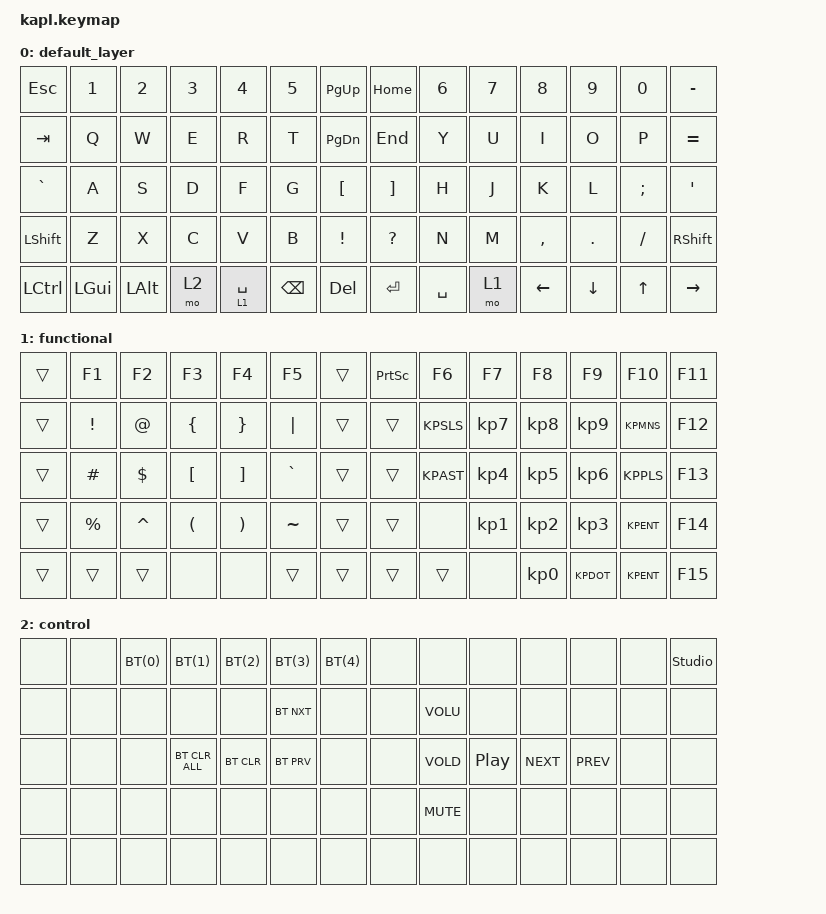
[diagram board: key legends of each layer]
#include <behaviors.dtsi>
#include <dt-bindings/zmk/keys.h>
#include <dt-bindings/zmk/bt.h>

#define FN_SPC &lt 1 SPACE

// for formatting reasons
#define KPAST KP_ASTERISK
#define KPSLS KP_SLASH
#define KPDOT KP_DOT
#define KPMNS KP_MINUS
#define KPPLS KP_PLUS
#define KPENT KP_ENTER

#define C_VOL_UP VOLU
#define C_VOL_DN VOLD
#define C_MUTE MUTE
#define C_NEXT NEXT
#define C_PREV PREV

#define BTC &bt BT_CLR
#define BTCA &bt BT_CLR_ALL
#define BTN &bt BT_NXT
#define BTP &bt BT_PRV

#define BT(a) &bt BT_SEL a

/ {
    keymap {
        compatible = "zmk,keymap";

        default_layer { // Layer 0
            // -------------------------------------
            // |    ESC    |     1     |     2     |     3     |     4     |     5     |    PGUP   |           |    HOME   |     6     |     7     |     8     |     9     |     0     |     -     |
            // |    TAB    |     Q     |     W     |     E     |     R     |     T     |    PGDN   |           |    END    |     Y     |     U     |     I     |     O     |     P     |     =     |
            // |     `     |     A     |     S     |     D     |     F     |     G     |     [     |           |     ]     |     H     |     J     |     K     |     L     |     ;     |     '     |
            // |   LSHFT   |     Z     |     X     |     C     |     V     |     B     |     !     |           |     ?     |     N     |     M     |     ,     |     .     |     /     |    RSFT   |
            // |   LCTRL   |    LGUI   |    LALT   |    MO1    |   SPC_FN  | |    BSPC   |    DEL    |       |    ENT    |    SPC    | |    MO1    |    LEFT   |    DOWN   |     UP    |    RGHT   |
            bindings = <
                &kp ESC   &kp N1    &kp N2    &kp N3    &kp N4    &kp N5    &kp PG_UP          &kp HOME  &kp N6    &kp N7    &kp N8    &kp N9    &kp N0    &kp MINUS
                &kp TAB   &kp Q     &kp W     &kp E     &kp R     &kp T     &kp PG_DN          &kp END   &kp Y     &kp U     &kp I     &kp O     &kp P     &kp EQUAL
                &kp GRAVE &kp A     &kp S     &kp D     &kp F     &kp G     &kp LBKT           &kp RBKT  &kp H     &kp J     &kp K     &kp L     &kp SEMI  &kp APOS
                &kp LSHFT &kp Z     &kp X     &kp C     &kp V     &kp B     &kp EXCL           &kp QMARK &kp N     &kp M     &kp COMMA &kp DOT   &kp FSLH  &kp RSHFT
                &kp LCTRL &kp LGUI  &kp LALT  &mo 2     FN_SPC    &kp BSPC  &kp DEL            &kp RET   &kp SPACE &mo 1     &kp LEFT  &kp DOWN  &kp UP    &kp RIGHT
            >;
        };

        functional { // Layer 1
            // -------------------------------------
            // |   trans   |    F1     |    F2     |    F3     |    F4     |    F5     |   trans   |           |   trans   |    F6     |    F7     |    F8     |    F9     |    F10    |    F11    |
            // |   trans   |     !     |     @     |     {     |     }     |     |     |   trans   |           |   trans   |    KP_/   |    KP_7   |    KP_8   |    KP_9   |    KP_-   |    F12    |
            // |   trans   |     #     |     $     |     [     |     ]     |     `     |   trans   |           |   trans   |    KP_*   |    KP_4   |    KP_5   |    KP_6   |    KP_+   |    F13    |
            // |   trans   |     %     |     ^     |     (     |     )     |     ~     |   trans   |           |   trans   |    none   |    KP_1   |    KP_2   |    KP_3   |   KP_ENT  |    F14    |
            // |   trans   |   trans   |   trans   |    none   |    none   | |   trans   |   trans   |       |   trans   |   trans   | |    none   |    KP_0   |    KP_.   |   KP_ENT  |    F15    |
            bindings = <
                &trans    &kp F1    &kp F2    &kp F3    &kp F4    &kp F5    &trans             &kp PSCRN &kp F6    &kp F7    &kp F8    &kp F9    &kp F10   &kp F11
                &trans    &kp EXCL  &kp AT    &kp LBRC  &kp RBRC  &kp PIPE  &trans             &trans    &kp KPSLS &kp KP_N7 &kp KP_N8 &kp KP_N9 &kp KPMNS &kp F12
                &trans    &kp HASH  &kp DLLR  &kp LBKT  &kp RBKT  &kp GRAVE &trans             &trans    &kp KPAST &kp KP_N4 &kp KP_N5 &kp KP_N6 &kp KPPLS &kp F13
                &trans    &kp PRCNT &kp CARET &kp LPAR  &kp RPAR  &kp TILDE &trans             &trans    &none     &kp KP_N1 &kp KP_N2 &kp KP_N3 &kp KPENT &kp F14
                &trans    &trans    &trans    &none     &none     &trans    &trans             &trans    &trans    &none     &kp KP_N0 &kp KPDOT &kp KPENT &kp F15
            >;
        };

        control { // Layer 2
            // -------------------------------------
            // |    none   |    none   |   BT(0)   |   BT(1)   |   BT(2)   |   BT(3)   |   BT(4)   |           |    none   |    none   |    none   |    none   |    none   |    none   |   STUDIO  |
            // |    none   |    none   |    none   |    none   |    none   |   BT_NXT  |    none   |           |    none   |   VOL_UP  |    none   |    none   |    none   |    none   |    none   |
            // |    none   |    none   |    none   | BT_CLR_ALL|   BT_CLR  |   BT_PRV  |    none   |           |    none   |   VOL_DN  | PLAY/PAUSE|    NEXT   |  PREVIOUS |    none   |    none   |
            // |    none   |    none   |    none   |    none   |    none   |    none   |    none   |           |    none   |    MUTE   |    none   |    none   |    none   |    none   |    none   |
            // |    none   |    none   |    none   |    none   |    none   | |     none   |    none  |       |    none   |    none   | |    none   |    none   |    none   |    none   |    none   |
            bindings = <
                &none     &none     BT(0)     BT(1)     BT(2)     BT(3)     BT(4)              &none     &none     &none     &none     &none     &none     &studio_unlock
                &none     &none     &none     &none     &none     BTN       &none              &none     &kp VOLU  &none     &none     &none     &none     &none
                &none     &none     &none     BTCA      BTC       BTP       &none              &none     &kp VOLD  &kp C_PP  &kp NEXT  &kp PREV  &none     &none
                &none     &none     &none     &none     &none     &none     &none              &none     &kp MUTE  &none     &none     &none     &none     &none
                &none     &none     &none     &none     &none     &none     &none              &none     &none     &none     &none     &none     &none     &none
            >;
        };
    };
 };
